# STM32N655 register map
File version: 1.0
CPU: CM55 r0p1, little endian, no MPU, FPU, vendor SysTick, 8 interrupt priority bits
Registers are 32-bit, read-write, reset 0x0 unless marked. A register's access mark holds for its fields unless they carry their own. Offsets are from the block's base; [hi:lo] are bit positions; {n}, {i} and the like mark numbered series.

## SAES — Secure AES coprocessor
Base 0x44021000
Same registers: SAES_S 0x54021000
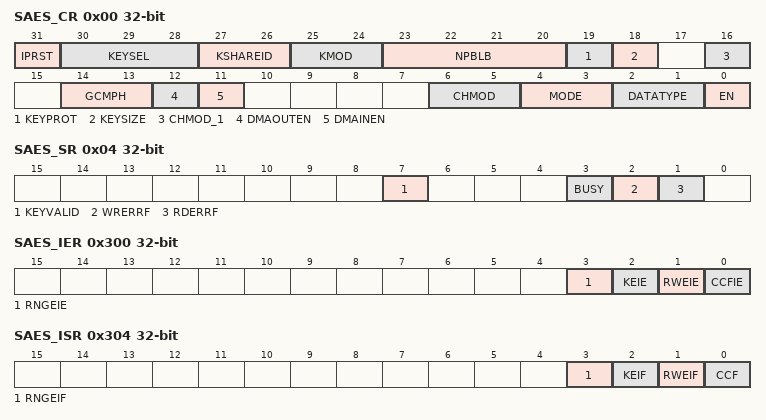
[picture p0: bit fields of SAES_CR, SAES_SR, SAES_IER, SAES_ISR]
0x00 SAES_CR — SAES control register
  [31] IPRST — SAES peripheral software reset
  [30:28] KEYSEL — Key selection
    0=Software key, loaded in key registers SAES_KEYx; 1=Derived hardware unique key (DHUK); 2=Boot hardware key (BHK); 4=XOR of DHUK and BHK; 7=Test mode key (256-bit hardware constant 0xA5A5...A5A5)
  [27:26] KSHAREID — Key share identification
    0=CRYP peripheral
  [25:24] KMOD — Key mode selection
    0=Normal key mode. Key registers are freely usable and no specific use or protection applies to SAES_DINR and SAES_DOUTR registers.; 1=Wrapped key mode. Key loaded in key registers can only be used to encrypt or decrypt AES keys. Hence, when a decryption is selected, read-as-zero SAES_DOUTR register is automatically loaded into SAES key registers after a successful decryption process.; 2=Shared key mode. After a successful decryption process, SAES key registers are shared with the peripheral described in KSHAREID[1:0] bitfield. This sharing is valid only while KMOD[1:0] at 0x2 and KEYVALID=1. When a decryption is selected, read-as-zero SAES_DOUTR register is automatically loaded into SAES key registers after a successful decryption process.
  [23:20] NPBLB — Number of padding bytes in last block
    0=All bytes are valid (no padding); 1=Padding for the last LSB byte; 15=Padding for the 15 LSB bytes of last block
  [19] KEYPROT — Key protection
    0=When KEYVALID is set and KEYSEL[2:0] = 0 application can transfer the ownership of the SAES, with its loaded key, to an application running in another security context (such as non-secure, secure); 1=When KEYVALID is set, key error flag (KEIF) is set when an access to any registers is detected, this access having a security context (for example, secure, non-secure) that does not match the one of the application that loaded the key
  [18] KEYSIZE — Key size selection
    0=128-bit; 1=256-bit
  [16] CHMOD_1 — CHMOD[2]
  [14:13] GCMPH — GCM or CCM phase selection
    0=Initialization phase; 1=Header phase; 2=Payload phase; 3=Final phase
  [12] DMAOUTEN — DMA output enable
    0=Disable; 1=Enable
  [11] DMAINEN — DMA input enable
    0=Disable; 1=Enable
  [6:5] CHMOD — CHMOD[1:0]: Chaining mode
    0=Electronic codebook (ECB); 1=Cipher-block chaining (CBC); 2=Counter mode (CTR); 3=Galois counter mode (GCM) and Galois message authentication code (GMAC)
  [4:3] MODE — Operating mode
    0=Encryption; 1=Key derivation (or key preparation), for ECB/CBC decryption only; 2=Decryption
  [2:1] DATATYPE
    0=No swapping (32-bit data); 1=Half-word swapping (16-bit data); 2=Byte swapping (8-bit data); 3=Bit-level swapping
  [0] EN — Enable
    0=Disable; 1=Enable
0x04 SAES_SR ro — SAES status register
  [7] KEYVALID — Key valid flag
    0=Key not valid; 1=Key valid
  [3] BUSY
    0=Idle; 1=Busy
  [2] WRERRF — Write error flag
    0=No error; 1=Unexpected write to SAES_DINR register occurred during computation or data output phase
  [1] RDERRF — Read error flag
    0=No error; 1=Unexpected read to SAES_DOUTR register occurred during computation or data input phase
0x08 SAES_DINR wo — SAES data input register
  [31:0] DIN — Data input
0x0C SAES_DOUTR ro — SAES data output register
  [31:0] DOUT — Data output
{0x10+4i} SAES_KEYR{i} wo (i=0..3) — SAES key register {i}
  [31:0] KEY — Cryptographic key, bits [{32i+31}:{32i}]
{0x20+4i} SAES_IVR{i} (i=0..3) — SAES initialization vector register {i}
  [31:0] IVI — Initialization vector input, bits [{32i+31}:{32i}]
{0x20+4i} SAES_KEYR{i} wo (i=4..7) — SAES key register {i}
  [31:0] KEY — Cryptographic key, bits [{32i+31}:{32i}]
{0x40+4i} SAES_SUSPR{i} (i=0..7) — SAES suspend registers
  [31:0] SUSP — Suspend data
0x300 SAES_IER — SAES interrupt enable register
  [all] fields
    0=Disabled (masked); 1=Enabled (not masked)
  [3] RNGEIE — RNG error interrupt enable
  [2] KEIE — Key error interrupt enable
  [1] RWEIE — Read or write error interrupt enable
  [0] CCFIE — Computation complete flag interrupt enable
0x304 SAES_ISR ro — SAES interrupt status register
  [3] RNGEIF — RNG error interrupt flag
    0=RNG bus is functional; 1=Error detected on RNG bus interface (random seed fetching error)
  [2] KEIF — Key error interrupt flag
    0=No key error detected; 1=Key information failed to load into key registers or the key register use is forbidden
  [1] RWEIF — Read or write error interrupt flag
    0=No read or write error detected; 1=Read or write error detected
  [0] CCF — Computation complete flag
    0=Not completed; 1=Completed
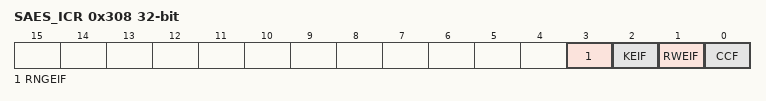
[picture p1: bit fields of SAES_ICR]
0x308 SAES_ICR wo — SAES interrupt clear register
  [3] RNGEIF — RNG error interrupt flag clear
  [2] KEIF — Key error interrupt flag clear
  [1] RWEIF — Read or write error interrupt flag clear
  [0] CCF — Computation complete flag clear
